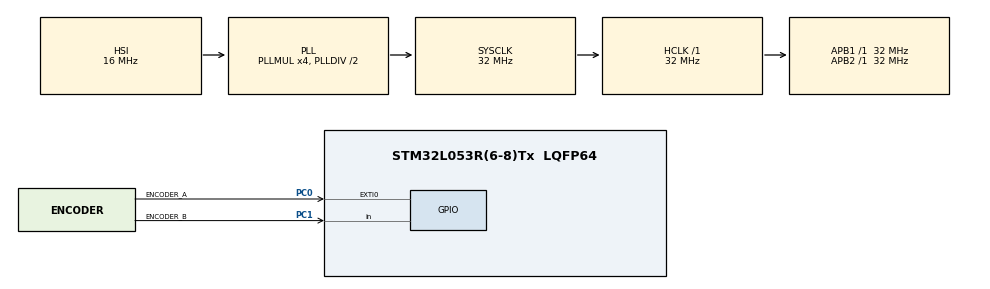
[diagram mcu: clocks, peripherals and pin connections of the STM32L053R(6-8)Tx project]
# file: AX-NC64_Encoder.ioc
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Mcu.Family=STM32L0
Mcu.Name=STM32L053R(6-8)Tx
Mcu.Package=LQFP64
NVIC.EXTI0_1_IRQn=true\:0\:0\:false\:false\:true\:true\:true
PC0.GPIO_Label=ENCODER_A
PC0.Signal=GPXTI0
PC1.GPIO_Label=ENCODER_B
PC1.Signal=GPIO_Input
ProjectManager.HeapSize=0x200
ProjectManager.StackSize=0x400
ProjectManager.TargetToolchain=MDK-ARM V5
RCC.AHBFreq_Value=32000000
RCC.APB1Freq_Value=32000000
RCC.APB1TimFreq_Value=32000000
RCC.APB2Freq_Value=32000000
RCC.APB2TimFreq_Value=32000000
RCC.HCLKFreq_Value=32000000
RCC.HSE_VALUE=8000000
RCC.HSI16_VALUE=16000000
RCC.HSI48_VALUE=48000000
RCC.HSI_VALUE=16000000
RCC.LSE_VALUE=32768
RCC.MSI_VALUE=2097000
RCC.PLLMUL=RCC_PLLMUL_4
RCC.SYSCLKFreq_VALUE=32000000
RCC.SYSCLKSource=RCC_SYSCLKSOURCE_PLLCLK
RCC.VCOOutputFreq_Value=64000000
board=custom

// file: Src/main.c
/* USER CODE BEGIN Header */
/**
  ******************************************************************************
  * @file           : main.c
  * @brief          : Main program body
  ******************************************************************************
  * @attention
  *
  * <h2><center>&copy; Copyright (c) 2019 STMicroelectronics.
  * All rights reserved.</center></h2>
  *
  * This software component is licensed by ST under BSD 3-Clause license,
  * the "License"; You may not use this file except in compliance with the
  * License. You may obtain a copy of the License at:
  *                        opensource.org/licenses/BSD-3-Clause
  *
  ******************************************************************************
  */
/* USER CODE END Header */

#include "main.h"

void SystemClock_Config(void);
static void MX_GPIO_Init(void);
/* USER CODE BEGIN PFP */
int16_t counter = 0;
/* USER CODE END PFP */

/* USER CODE BEGIN 0 */
void HAL_GPIO_EXTI_Callback(uint16_t GPIO_Pin) {
  if (GPIO_Pin == ENCODER_A_Pin) {
		if (HAL_GPIO_ReadPin(ENCODER_B_GPIO_Port, ENCODER_B_Pin) == 0) {
			counter++;
		} else {
			counter--;
		}
	}
}
/* USER CODE END 0 */

int main(void)
{

  /* MCU Configuration--------------------------------------------------------*/

  /* Reset of all peripherals, Initializes the Flash interface and the Systick. */
  HAL_Init();

  /* Configure the system clock */
  SystemClock_Config();

  /* Initialize all configured peripherals */
  MX_GPIO_Init();

  /* Infinite loop */
  /* USER CODE BEGIN WHILE */
  while (1)
  {
		// Use variable counter to do somethings

    /* USER CODE END WHILE */

  }
}

void SystemClock_Config(void)
{
  RCC_OscInitTypeDef RCC_OscInitStruct = {0};
  RCC_ClkInitTypeDef RCC_ClkInitStruct = {0};

  /** Configure the main internal regulator output voltage
  */
  __HAL_PWR_VOLTAGESCALING_CONFIG(PWR_REGULATOR_VOLTAGE_SCALE1);
  /** Initializes the CPU, AHB and APB busses clocks
  */
  RCC_OscInitStruct.OscillatorType = RCC_OSCILLATORTYPE_HSI;
  RCC_OscInitStruct.HSIState = RCC_HSI_ON;
  RCC_OscInitStruct.HSICalibrationValue = RCC_HSICALIBRATION_DEFAULT;
  RCC_OscInitStruct.PLL.PLLState = RCC_PLL_ON;
  RCC_OscInitStruct.PLL.PLLSource = RCC_PLLSOURCE_HSI;
  RCC_OscInitStruct.PLL.PLLMUL = RCC_PLLMUL_4;
  RCC_OscInitStruct.PLL.PLLDIV = RCC_PLLDIV_2;
  if (HAL_RCC_OscConfig(&RCC_OscInitStruct) != HAL_OK)
  {
    Error_Handler();
  }
  /** Initializes the CPU, AHB and APB busses clocks
  */
  RCC_ClkInitStruct.ClockType = RCC_CLOCKTYPE_HCLK|RCC_CLOCKTYPE_SYSCLK
                              |RCC_CLOCKTYPE_PCLK1|RCC_CLOCKTYPE_PCLK2;
  RCC_ClkInitStruct.SYSCLKSource = RCC_SYSCLKSOURCE_PLLCLK;
  RCC_ClkInitStruct.AHBCLKDivider = RCC_SYSCLK_DIV1;
  RCC_ClkInitStruct.APB1CLKDivider = RCC_HCLK_DIV1;
  RCC_ClkInitStruct.APB2CLKDivider = RCC_HCLK_DIV1;

  if (HAL_RCC_ClockConfig(&RCC_ClkInitStruct, FLASH_LATENCY_1) != HAL_OK)
  {
    Error_Handler();
  }
}

static void MX_GPIO_Init(void)
{
  GPIO_InitTypeDef GPIO_InitStruct = {0};

  /* GPIO Ports Clock Enable */
  __HAL_RCC_GPIOC_CLK_ENABLE();

  /*Configure GPIO pin : ENCODER_A_Pin */
  GPIO_InitStruct.Pin = ENCODER_A_Pin;
  GPIO_InitStruct.Mode = GPIO_MODE_IT_RISING;
  GPIO_InitStruct.Pull = GPIO_NOPULL;
  HAL_GPIO_Init(ENCODER_A_GPIO_Port, &GPIO_InitStruct);

  /*Configure GPIO pin : ENCODER_B_Pin */
  GPIO_InitStruct.Pin = ENCODER_B_Pin;
  GPIO_InitStruct.Mode = GPIO_MODE_INPUT;
  GPIO_InitStruct.Pull = GPIO_NOPULL;
  HAL_GPIO_Init(ENCODER_B_GPIO_Port, &GPIO_InitStruct);

  /* EXTI interrupt init*/
  HAL_NVIC_SetPriority(EXTI0_1_IRQn, 0, 0);
  HAL_NVIC_EnableIRQ(EXTI0_1_IRQn);

}

void Error_Handler(void)
{
}

/************************ (C) COPYRIGHT STMicroelectronics *****END OF FILE****/
